# MCAN0_CFG register map
Vendor: Texas Instruments
Registers are 32-bit, access per field, reset 0x0 unless marked. A register's access mark holds for its fields unless they carry their own. Offsets are as the file gives them; [hi:lo] are bit positions.

## MCAN0_CFG (part 2 of 2)
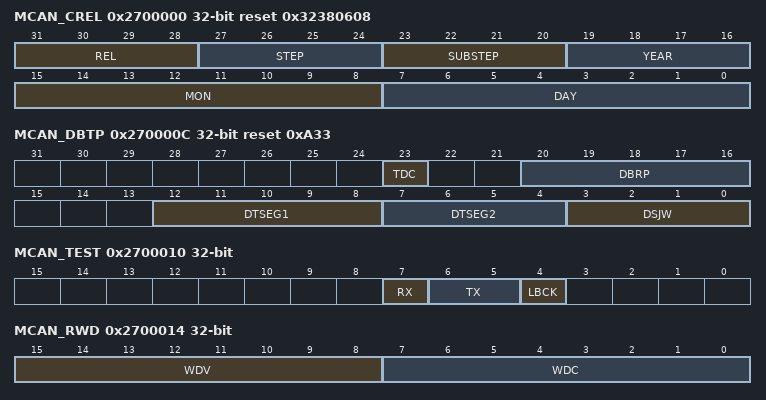
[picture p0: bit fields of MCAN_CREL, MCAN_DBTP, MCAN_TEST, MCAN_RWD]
0x2700000 MCAN_CREL ro reset 0x32380608 — Core Release Register Release dependent constant (version + date).
  [31:28] REL — Core Release One digit, BCD-coded.
  [27:24] STEP — Step of Core Release One digit, BCD-coded.
  [23:20] SUBSTEP — Sub-step of Core Release One digit, BCD-coded.
  [19:16] YEAR — Time Stamp Year One digit, BCD-coded.
  [15:8] MON — Time Stamp Month Two digits, BCD-coded.
  [7:0] DAY — Time Stamp Day Two digits, BCD-coded.
0x2700004 MCAN_ENDN ro reset 0x87654321 — Endian Register Constant 8765 4321h.
  [31:0] ETV — Endianness Test Value The endianness test value is 8765 4321h.
0x270000C MCAN_DBTP reset 0xA33 — Data Bit Timing & Prescaler Register Configuration of data phase bit timing, transmitter delay compensation enable. This register is only writable if the [1] CCE and [0] INIT bits are set. The CAN bit time may be programed in the range of 4 to 49 time quanta. The CAN time quantum may be programmed in the range of 1 to 32 MCAN functional clock periods. tq = ([20-16] DBRP + 1) mtq (minimum time quantum = CAN clock period (MCAN functional clock)). The [12-8] DTSEG1 field is the sum of Prop_Seg and Phase_Seg1. The [7-4] DTSEG2 field is Phase_Seg2. Therefore the length of the bit time is (programmed values) [[12-8] DTSEG1 + [7-4] DTSEG2 + 3] tq or (functional values) [Sync_Seg + Prop_Seg + Phase_Seg1 + Phase_Seg2] tq. The Information Processing Time (IPT) is zero, meaning the data for the next bit is available at the first clock edge after the sample point. Note: With a CAN clock (MCAN functional clock) of 8 MHz, the reset value of 0000 0A33h configures the MCAN module for a data phase bit rate of 500 kbit/s. Note: The bit rate configured for the CAN FD data phase via the register must be higher or equal to the bit rate configured for the arbitration phase via the register.
  [23] TDC rw — Transmitter Delay Compensation 0h = Transmitter Delay Compensation disabled 1h = Transmitter Delay Compensation enabled
  [20:16] DBRP rw — Data Baud Rate Prescaler The value by which the oscillator frequency is divided for generating the bit time quanta. The bit time is built up from a multiple of this quanta. Valid values for the Baud Rate Prescaler are 0 to 31 (0h-1Fh). The actual interpretation by the hardware of this value is such that one more than the value programmed here is used.
  [12:8] DTSEG1 rw — Data time segment before sample point Valid values are 0 to 31 (0h-1Fh). The actual interpretation by the hardware of this value is such that one more than the programmed value is used.
  [7:4] DTSEG2 rw — Data time segment after sample point Valid values are 0 to 15 (0h-Fh). The actual interpretation by the hardware of this value is such that one more than the programmed value is used.
  [3:0] DSJW rw — Data (Re)Synchronization Jump Width Valid values are 0 to 15 (0h-Fh). The actual interpretation by the hardware of this value is such that one more than the value programmed here is used.
0x2700010 MCAN_TEST — Test Register Test mode selection. Write access to the register has to be enabled by setting the [7] TEST bit. All register functions are set to their reset values when the [7] TEST bit is reset. Loopback Mode and software control of the MCAN TX pin are hardware test modes. Programming of the [6-5] TX field ≠ 00 may disturb the message transfer on the CAN bus.
  [7] RX ro — Receive Pin Monitors the actual value of the MCAN RX pin 0h = The CAN bus is dominant (MCAN RX = 0h) 1h = The CAN bus is recessive (MCAN RX = 1h)
  [6:5] TX rw — Control of Transmit Pin 0h = Reset value, the MCAN TX pin controlled by the CAN Core, updated at the end of the CAN bit time 1h = Sample Point can be monitored at the MCAN TX pin 2h = Dominant ('0') level at the MCAN TX pin 3h = Recessive ('1') at the MCAN TX pin
  [4] LBCK rw — Loopback Mode 0h = Reset value, Loopback Mode is disabled 1h = Loopback Mode is enabled (see , Test Modes)
0x2700014 MCAN_RWD — RAM Watchdog Monitors the READY output of the Message RAM. The RAM Watchdog monitors the READY output of the Message RAM. A Message RAM access starts the Message RAM Watchdog Counter with the value configured by the [7-0] WDC field. The counter is reloaded with the [7-0] WDC field when the Message RAM signals successful completion by activating its READY output. In case there is no response from the Message RAM until the counter has counted down to zero, the counter stops and interrupt flag [26] WDI is set. The RAM Watchdog Counter is clocked by the Host clock (MCAN interface clock).
  [15:8] WDV ro — Watchdog Value Actual Message RAM Watchdog Counter Value.
  [7:0] WDC rw — Watchdog Configuration Start value of the Message RAM Watchdog Counter. With the reset value of 0h the counter is disabled.
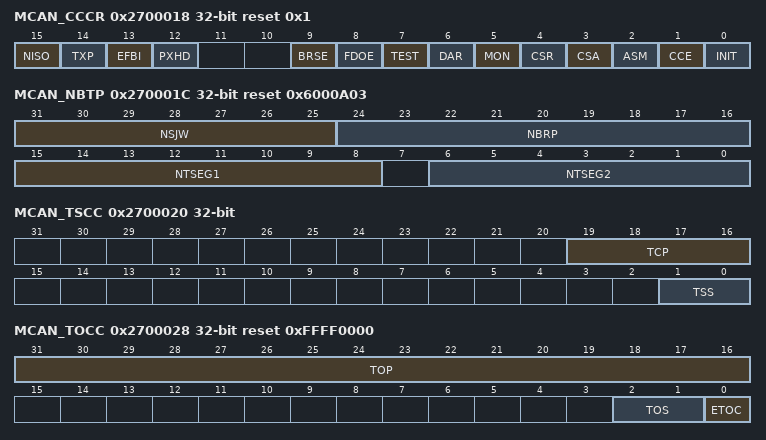
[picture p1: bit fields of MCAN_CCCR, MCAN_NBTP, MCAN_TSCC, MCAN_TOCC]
0x2700018 MCAN_CCCR reset 0x1 — CC Control Register Operation mode configuration. For details about setting and resetting of single bits, see , Software Initialization.
  [15] NISO rw — Non ISO Operation 0h = CAN FD frame format according to ISO 11898-1:2015. 1h = CAN FD frame format according to Bosch CAN FD Specification 1.0.
  [14] TXP rw — Transmit Pause If this bit is set, the MCAN module pauses for two CAN bit times before starting the next transmission after itself has successfully transmitted a frame (see , Tx Handling) . 0h = Transmit pause disabled 1h = Transmit pause enabled
  [13] EFBI rw — Edge Filtering during Bus Integration 0h = Edge filtering disabled 1h = Two consecutive dominant t
  [12] PXHD rw — Protocol Exception Handling Disable 0h = Protocol exception handling enabled 1h = Protocol exception handling disabled Note:When protocol exception handling is disabled, the MCAN module will transmit an error frame when it detects a protocol exception condition.
  [9] BRSE rw — Bit Rate Switch Enable 0h = Bit rate switching for transmissions disabled 1h = Bit rate switching for transmissions enabled Note:When CAN FD operation is disabled the MCAN_CCCR[8] FDOE = 0h, the MCAN_CCCR[9] BRSE bit is not evaluated.
  [8] FDOE rw — FD Operation Enable 0h = FD operation disabled 1h = FD operation enabled
  [7] TEST rw — Test Mode Enable 0h = Normal operation. The 1h = Test Mode. Write access to the
  [6] DAR rw — Disable Automatic Retransmission 0h = Automatic retransmission of messages not transmitted successfully enabled 1h = Automatic retransmission disabled
  [5] MON rw — Bus Monitoring Mode The 0h = Bus Monitoring Mode is disabled 1h = Bus Monitoring Mode is enabled
  [4] CSR rw — Clock Stop Request 0h = No clock stop is requested 1h = Clock stop requested. When clock stop is requested, first the
  [3] CSA ro — Clock Stop Acknowledge 0h = No clock stop acknowledged 1h = The MCAN module may be set in power down by stopping MCAN interface clock and MCAN functional clock
  [2] ASM rw — Restricted Operation Mode The 0h = Normal CAN operation 1h = Restricted Operation Mode active
  [1] CCE rw — Configuration Change Enable 0h = The Host CPU has no write access to the protected configuration registers 1h = The Host CPU has write access to the protected configuration registers (while the
  [0] INIT rw — Initialization 0h = Normal Operation 1h = Initialization is started Note:Due to the synchronization mechanism between the two clock domains, there may be a delay until the value written to the MCAN_CCCR[0] INIT bit can be read back. Therefore the software has to assure that the previous value written to the MCAN_CCCR[0] INIT bit has been accepted by reading the MCAN_CCCR[0] INIT bit before setting the MCAN_CCCR[0] INIT bit to a new value.
0x270001C MCAN_NBTP reset 0x6000A03 — Nominal Bit Timing & Prescaler Register Configuration of arbitration phase bit timing. This register is only writable if the [1] CCE and [0] INIT bits are set. The CAN bit time may be programed in the range of 4 to 385 time quanta. The CAN time quantum may be programmed in the range of 1 to 512 MCAN functional clock periods. tq = ([24-16] NBRP + 1) mtq. The [15-8] NTSEG1 field is the sum of Prop_Seg and Phase_Seg1. The [6-0] NTSEG2 field is Phase_Seg2. Therefore the length of the bit time is (programmed values) [[15-8] NTSEG1 + [6-0] NTSEG2 + 3] tq or (functional values) [Sync_Seg + Prop_Seg + Phase_Seg1 + Phase_Seg2] tq. The Information Processing Time (IPT) is zero, meaning the data for the next bit is available at the first clock edge after the sample point.
  [31:25] NSJW rw — Nominal (Re)Synchronization Jump Width Valid values are 0 to 127 (0h-7Fh). The actual interpretation by the hardware of this value is such that one more than the value programmed here is used.
  [24:16] NBRP rw — Nominal Baud Rate Prescaler The value by which the oscillator frequency is divided for generating the bit time quanta. The bit time is built up from a multiple of this quanta. Valid values for the Baud Rate Prescaler are 0 to 511 (0h-1FFh). The actual interpretation by the hardware of this value is such that one more than the value programmed here is used.
  [15:8] NTSEG1 rw — Nominal Time segment before sample point Valid values are 1 to 255 (1h-FFh). The actual interpretation by the hardware of this value is such that one more than the programmed value is used.
  [6:0] NTSEG2 rw — Nominal Time segment after sample point Valid values are 0 to 127 (0h-7Fh). The actual interpretation by the hardware of this value is such that one more than the programmed value is used. Note:With a CAN clock (MCAN functional clock) of 8 MHz, the reset value of 0600 0A03h configures the MCAN module for a bit rate of 500 kbit/s.
0x2700020 MCAN_TSCC — Timestamp Counter Configuration Timestamp counter prescaler setting, selection of internal/external timestamp vector. For a description of the Timestamp Counter, see , Timestamp Generation.
  [19:16] TCP rw — Timestamp Counter Prescaler Configures the timestamp and timeout counters time unit in multiples of CAN bit times [1-16 (0h-Fh)]. The actual interpretation by the hardware of this value is such that one more than the value programmed here is used. Note:With CAN FD an external counter is required for timestamp generation (MCAN_TSCC[1-0] TSS = 2h)
  [1:0] TSS rw — Timestamp Select 0h = Timestamp counter value always 0h 1h = Timestamp counter value incremented according to the 2h = External timestamp counter value used 3h = Same as 0h
0x2700024 MCAN_TSCV access not given — Timestamp Counter Value Read/reset timestamp counter.
  [15:0] TSC — Timestamp Counter The internal/external Timestamp Counter value is captured on start of frame (both Rx and Tx). When the [1-16] depending on the configuration of the Write access resets the counter to zero. When the Note:A 'wrap around' is a change of the Timestamp Counter value from non-zero to zero not caused by write access to the MCAN_TSCV register. (access RWTC)
0x2700028 MCAN_TOCC reset 0xFFFF0000 — Timeout Counter Configuration Configuration of timeout period, selection of timeout counter operation mode. For a description of the Timeout Counter, see , Timeout Counter.
  [31:16] TOP rw — Timeout Period Start value of the Timeout Counter (down-counter). Configures the Timeout Period.
  [2:1] TOS rw — Timeout Select When operating in Continuous mode, a write to the 0h = Continuous operation 1h = Timeout controlled by Tx Event FIFO 2h = Timeout controlled by Rx FIFO 0 3h = Timeout controlled by Rx FIFO 1
  [0] ETOC rw — Enable Timeout Counter 0h = Timeout Counter disabled 1h = Timeout Counter enabled
0x270002C MCAN_TOCV access not given reset 0xFFFF — Timeout Counter Value Read/reset timeout counter.
  [15:0] TOC — Timeout Counter The Timeout Counter is decremented in multiples of CAN bit times [1-16] depending on the configuration of the (access RWTC)
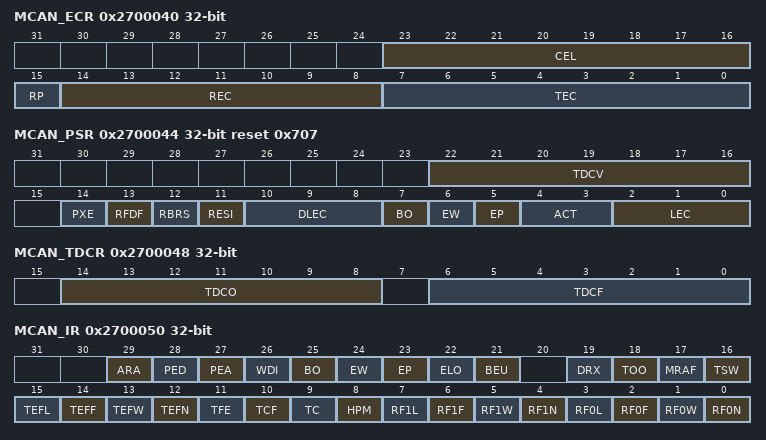
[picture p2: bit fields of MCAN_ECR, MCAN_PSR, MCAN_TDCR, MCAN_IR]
0x2700040 MCAN_ECR ro — Error Counter Register State of Rx/Tx Error Counter, CAN Error Logging.
  [23:16] CEL — CAN Error Logging The counter is incremented each time when a CAN protocol error causes the Transmit Error Counter or the Receive Error Counter to be incremented. It is reset by read access to the
  [15] RP — Receive Error Passive 0h = The Receive Error Counter is below the error passive level of 128 1h = The Receive Error Counter has reached the error passive level of 128
  [14:8] REC — Receive Error Counter Actual state of the Receive Error Counter, values between 0 and 127.
  [7:0] TEC — Transmit Error Counter Actual state of the Transmit Error Counter, values between 0 and 255. Note:When the MCAN_CCCR[2] ASM bit is set, the CAN protocol controller does not increment the MCAN_ECR[7-0] TEC and MCAN_ECR[14-8] REC fields when a CAN protocol error is detected, but the MCAN_ECR[23-16] CEL field is still incremented.
0x2700044 MCAN_PSR ro reset 0x707 — Protocol Status Register CAN protocol controller status, transmitter delay compensation value.
  [22:16] TDCV — Transmitter Delay Compensation Value Position of the secondary sample point, defined by the sum of the measured delay from the MCAN TX to MCAN RX pins and the
  [14] PXE — Protocol Exception Event 0h = No protocol exception event occurred since last read access 1h = Protocol exception event occurred
  [13] RFDF — Received a CAN FD Message This bit is set independent of acceptance filtering. 0h = Since this bit was reset by the Host CPU, no CAN FD message has been received 1h = Message in CAN FD format with FDF flag set has been received
  [12] RBRS — BRS flag of last received CAN FD Message This bit is set together with the 0h = Last received CAN FD message did not have its BRS flag set 1h = Last received CAN FD message had its BRS flag set
  [11] RESI — ESI flag of last received CAN FD Message This bit is set together with the 0h = Last received CAN FD message did not have its ESI flag set 1h = Last received CAN FD message had its ESI flag set
  [10:8] DLEC — Data Phase Last Error Code Type of last error that occurred in the data phase of a CAN FD format frame with its BRS flag set. Coding is the same as for the
  [7] BO — Bus_Off Status 0h = The MCAN module is not Bus_Off 1h = The MCAN module is in Bus_Off state
  [6] EW — Warning Status 0h = Both error counters are below the Error_Warning limit of 96 1h = At least one of error counter has reached the Error_Warning limit of 96
  [5] EP — Error Passive 0h = The MCAN module is in the Error_Active state. It normally takes part in bus communication and sends an active error flag when an error has been detected 1h = The MCAN module is in the Error_Passive state
  [4:3] ACT — Activity Monitors the module's CAN communication state. 0h = Synchronizing - node is synchronizing on CAN communication 1h = Idle - node is neither receiver nor transmitter 2h = Receiver - node is operating as receiver 3h = Transmitter - node is operating as transmitter Note:ACT is set to 0h by a Protocol Exception Event.
  [2:0] LEC — Last Error Code The 0h = No Error: No error occurred since the 1h = Stuff Error: More than 5 equal bits in a sequence have occurred in a part of a received message where this is not allowed. 2h = Form Error: A fixed format part of a received frame has the wrong format. 3h = AckError: The message transmitted by the MCAN module was not acknowledged by another node. 4h = Bit1Error: During the transmission of a message (with the exception of the arbitration field), the device wanted to send a recessive level (bit of logical value '1'), but the monitored bus value was dominant. 5h = Bit0Error: During the transmission of a message (or acknowledge bit, or active error flag, or overload flag), the device wanted to send a dominant level (data or identifier bit logical value 0), but the monitored bus value was recessive. During Bus_Off recovery this status is set each time a sequence of 11 recessive bits has been monitored. This enables the Host CPU to monitor the proceeding of the Bus_Off recovery sequence (indicating the bus is not stuck at dominant or continuously disturbed). 6h = CRCError: The CRC check sum of a received message was incorrect. The CRC of an incom-ing message does not match with the CRC calculated from the received data. 7h = NoChange: Any read access to the Protocol Status Register re-initializes the Note:When a frame in CAN FD format has reached the data phase with BRS flag set, the next CAN event (error or valid frame) will be shown in the MCAN_PSR[10-8] DLEC field instead of the MCAN_PSR[2-0] LEC field. An error in a fixed stuff bit of a CAN FD CRC sequence will be shown as a Form Error, not Stuff Error.
0x2700048 MCAN_TDCR — Transmitter Delay Comensation Register Configuration of transmitter delay compensation offset and filter window length.
  [14:8] TDCO rw — Transmitter Delay Compensation Offset Offset value defining the distance between the measured delay from the MCAN RX and MCAN TX pins and the secondary sample point. Valid values are 0 to 127 mtq (0h-7Fh).
  [6:0] TDCF rw — Transmitter Delay Compensation Filter Window Length Defines the minimum value for the SSP position, dominant edges on the MCAN RX pin that would result in an earlier SSP position are ignored for transmitter delay measure-ment. The feature is enabled when the
0x2700050 MCAN_IR access not given — Interrupt Register The flags are set when one of the listed conditions is detected (edge-sensitive). The flags remain set until the Host CPU clears them. A flag is cleared by writing a 1h to the corresponding bit position. Writing a 0h has no effect. A hard reset will clear the register. The configuration of the register controls whether an interrupt is generated. The configuration of the register controls on which interrupt line an interrupt is signalled.
  [29] ARA — Access to Reserved Address 0h = No access to reserved address occurred 1h = Access to reserved address occurred (access RW1TC)
  [28] PED — Protocol Error in Data Phase 0h = No protocol error in data phase 1h = Protocol error in data phase detected ( (access RW1TC)
  [27] PEA — Protocol Error in Arbitration Phase 0h = No protocol error in arbitration phase 1h = Protocol error in arbitration phase detected ( (access RW1TC)
  [26] WDI — Watchdog Interrupt 0h = No Message RAM Watchdog event occurred 1h = Message RAM Watchdog event due to missing READY (access RW1TC)
  [25] BO — Bus_Off Status 0h = Bus_Off status unchanged 1h = Bus_Off status changed (access RW1TC)
  [24] EW — Warning Status 0h = Error_Warning status unchanged 1h = Error_Warning status changed (access RW1TC)
  [23] EP — Error Passive 0h = Error_Passive status unchanged 1h = Error_Passive status changed (access RW1TC)
  [22] ELO — Error Logging Overflow 0h = CAN Error Logging Counter did not overflow 1h = Overflow of CAN Error Logging Counter occurred (access RW1TC)
  [21] BEU — Bit Error Uncorrected Message RAM bit error detected, uncorrected. Controlled by input signal generated by parity/ECC logic attached to the Message RAM. An uncorrected Message RAM bit error sets the 0h = No bit error detected when reading from Message RAM 1h = Bit error detected, uncorrected (example: parity logic) (access RW1TC)
  [19] DRX — Message stored to Dedicated Rx Buffer The flag is set whenever a received message has been stored into a dedicated Rx Buffer. 0h = No Rx Buffer updated 1h = At least one received message stored into an Rx Buffer (access RW1TC)
  [18] TOO — Timeout Occurred 0h = No timeout 1h = Timeout reached (access RW1TC)
  [17] MRAF — Message RAM Access Failure The flag is set, when the Rx Handler: a) has not completed acceptance filtering or storage of an accepted message until the arbitration field of the following message has been received. In this case acceptance filtering or message storage is aborted and the Rx Handler starts processing of the following message. b) was not able to write a message to the Message RAM. In this case message storage is aborted. In both cases the FIFO put index is not updated respectively the New Data flag for a dedicated Rx Buffer is not set, a partly stored message is overwritten when the next message is stored to this location. The flag is also set when the Tx Handler was not able to read a message from the Message RAM in time. In this case message transmission is aborted. In case of a Tx Handler access failure the MCAN module is switched into Restricted Operation Mode (see 0h = No Message RAM access failure occurred 1h = Message RAM access failure occurred (access RW1TC)
  [16] TSW — Timestamp Wraparound 0h = No timestamp counter wrap-around 1h = Timestamp counter wrapped around (access RW1TC)
  [15] TEFL — Tx Event FIFO Element Lost 0h = No Tx Event FIFO element lost 1h = Tx Event FIFO element lost, also set after write attempt to Tx Event FIFO of size zero (access RW1TC)
  [14] TEFF — Tx Event FIFO Full 0h = Tx Event FIFO not full 1h = Tx Event FIFO full (access RW1TC)
  [13] TEFW — Tx Event FIFO Watermark Reached 0h = Tx Event FIFO fill level below watermark 1h = Tx Event FIFO fill level reached watermark (access RW1TC)
  [12] TEFN — Tx Event FIFO New Entry 0h = Tx Event FIFO unchanged 1h = Tx Handler wrote Tx Event FIFO element (access RW1TC)
  [11] TFE — Tx FIFO Empty 0h = Tx FIFO non-empty 1h = Tx FIFO empty (access RW1TC)
  [10] TCF — Transmission Cancellation Finished 0h = No transmission cancellation finished 1h = Transmission cancellation finished (access RW1TC)
  [9] TC — Transmission Completed 0h = No transmission completed 1h = Transmission completed (access RW1TC)
  [8] HPM — High Priority Message 0h = No high priority message received 1h = High priority message received (access RW1TC)
  [7] RF1L — Rx FIFO 1 Message Lost 0h = No Rx FIFO 1 message lost 1h = Rx FIFO 1 message lost, also set after write attempt to Rx FIFO 1 of size zero (access RW1TC)
  [6] RF1F — Rx FIFO 1 Full 0h = Rx FIFO 1 not full 1h = Rx FIFO 1 full (access RW1TC)
  [5] RF1W — Rx FIFO 1 Watermark Reached 0h = Rx FIFO 1 fill level below watermark 1h = Rx FIFO 1 fill level reached watermark (access RW1TC)
  [4] RF1N — Rx FIFO 1 New Message 0h = No new message written to Rx FIFO 1 1h = New message written to Rx FIFO 1 (access RW1TC)
  [3] RF0L — Rx FIFO 0 Message Lost 0h = No Rx FIFO 0 message lost 1h = Rx FIFO 0 message lost, also set after write attempt to Rx FIFO 0 of size zero (access RW1TC)
  [2] RF0F — Rx FIFO 0 Full 0h = Rx FIFO 0 not full 1h = Rx FIFO 0 full (access RW1TC)
  [1] RF0W — Rx FIFO 0 Watermark Reached 0h = Rx FIFO 0 fill level below watermark 1h = Rx FIFO 0 fill level reached watermark (access RW1TC)
  [0] RF0N — Rx FIFO 0 New Message 0h = No new message written to Rx FIFO 0 1h = New message written to Rx FIFO 0 (access RW1TC)
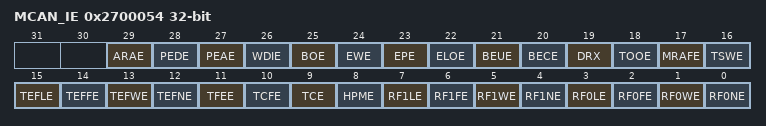
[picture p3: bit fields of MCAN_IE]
0x2700054 MCAN_IE — Interrupt Enable The settings in the Interrupt Enable register determine which status changes in the register are signalled on an interrupt line.
  [29] ARAE rw — Access to Reserved Address Enable 0h = Interrupt disabled 1h = Interrupt enabled
  [28] PEDE rw — Protocol Error in Data Phase Enable 0h = Interrupt disabled 1h = Interrupt enabled
  [27] PEAE rw — Protocol Error in Arbitration Phase Enable 0h = Interrupt disabled 1h = Interrupt enabled
  [26] WDIE rw — Watchdog Interrupt Enable 0h = Interrupt disabled 1h = Interrupt enabled
  [25] BOE rw — Bus_Off Status Interrupt Enable 0h = Interrupt disabled 1h = Interrupt enabled
  [24] EWE rw — Warning Status Interrupt Enable 0h = Interrupt disabled 1h = Interrupt enabled
  [23] EPE rw — Error Passive Interrupt Enable 0h = Interrupt disabled 1h = Interrupt enabled
  [22] ELOE rw — Error Logging Overflow Interrupt Enable 0h = Interrupt disabled 1h = Interrupt enabled
  [21] BEUE rw — Bit Error Uncorrected Interrupt Enable 0h = Interrupt disabled 1h = Interrupt enabled
  [20] BECE rw — Bit Error Corrected Interrupt Enable 0h = Interrupt disabled 1h = Interrupt enabled
  [19] DRX rw — Message stored to Dedicated Rx Buffer Interrupt Enable
  [18] TOOE rw — Timeout Occurred Interrupt Enable 0h = Interrupt disabled 1h = Interrupt enabled
  [17] MRAFE rw — Message RAM Access Failure Interrupt Enable 0h = Interrupt disabled 1h = Interrupt enabled
  [16] TSWE rw — Timestamp Wraparound Interrupt Enable 0h = Interrupt disabled 1h = Interrupt enabled
  [15] TEFLE rw — Tx Event FIFO Event Lost Interrupt Enable 0h = Interrupt disabled 1h = Interrupt enabled
  [14] TEFFE rw — Tx Event FIFO Full Interrupt Enable 0h = Interrupt disabled 1h = Interrupt enabled
  [13] TEFWE rw — Tx Event FIFO Watermark Reached Interrupt Enable 0h = Interrupt disabled 1h = Interrupt enabled
  [12] TEFNE rw — Tx Event FIFO New Entry Interrupt Enable 0h = Interrupt disabled 1h = Interrupt enabled
  [11] TFEE rw — Tx FIFO Empty Interrupt Enable 0h = Interrupt disabled 1h = Interrupt enabled
  [10] TCFE rw — Transmission Cancellation Finished Interrupt Enable 0h = Interrupt disabled 1h = Interrupt enabled
  [9] TCE rw — Transmission Completed Interrupt Enable 0h = Interrupt disabled 1h = Interrupt enabled
  [8] HPME rw — High Priority Message Interrupt Enable 0h = Interrupt disabled 1h = Interrupt enabled
  [7] RF1LE rw — Rx FIFO 1 Message Lost Interrupt Enable 0h = Interrupt disabled 1h = Interrupt enabled
  [6] RF1FE rw — Rx FIFO 1 Full Interrupt Enable 0h = Interrupt disabled 1h = Interrupt enabled
  [5] RF1WE rw — Rx FIFO 1 Watermark Reached Interrupt Enable 0h = Interrupt disabled 1h = Interrupt enabled
  [4] RF1NE rw — Rx FIFO 1 New Message Interrupt Enable 0h = Interrupt disabled 1h = Interrupt enabled
  [3] RF0LE rw — Rx FIFO 0 Message Lost Interrupt Enable 0h = Interrupt disabled 1h = Interrupt enabled
  [2] RF0FE rw — Rx FIFO 0 Full Interrupt Enable 0h = Interrupt disabled 1h = Interrupt enabled
  [1] RF0WE rw — Rx FIFO 0 Watermark Reached Interrupt Enable 0h = Interrupt disabled 1h = Interrupt enabled
  [0] RF0NE rw — Rx FIFO 0 New Message Interrupt Enable 0h = Interrupt disabled 1h = Interrupt enabled
